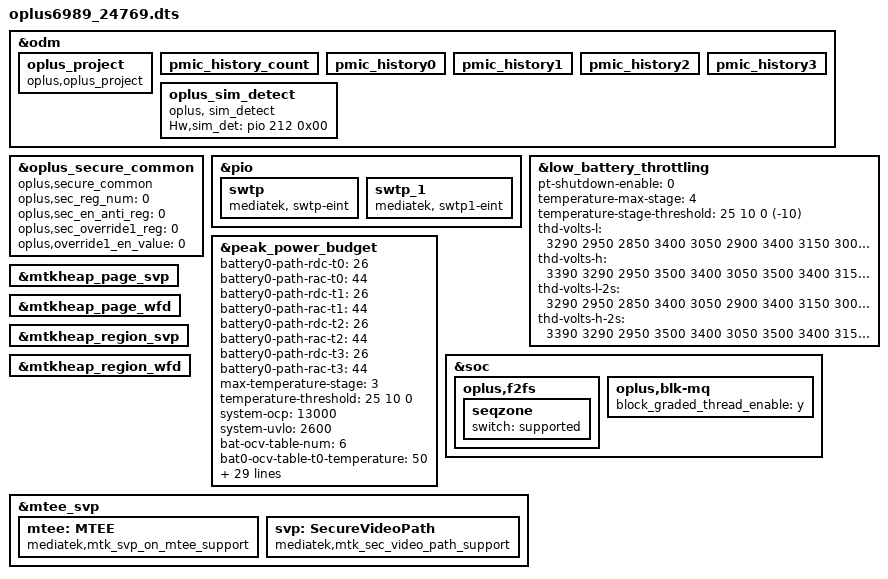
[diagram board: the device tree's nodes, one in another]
// SPDX-License-Identifier: (GPL-2.0 OR MIT)
/*
 * Copyright (C) 2022 MediaTek Inc.
 */
#include "k6989v2_64.dts"

/* Add for CaymanP(24769) fingerprint device-tree */
/* #ifdef CONFIG_UFF_FINGERPRINT */
#include "mediatek/oplus_uff_24610.dtsi"
/* #endif CONFIG_UFF_FINGERPRINT */

//#ifdef OPLUS_FEATURE_SENSOR
#include "mediatek/oplus_sensor_24622.dtsi"
//#endif
//#ifdef OPLUS_FEATURE_CHG_BASIC

//endif

&odm {
    /*OPLUS_FEATURE_OEM_OCDT oppo project start */
	oplus_project:oplus_project {
		compatible = "oplus,oplus_project";
	};

	pmic_history_count:pmic_history_count {
 	};
 	pmic_history0:pmic_history0 {
 	};
 	pmic_history1:pmic_history1 {
 	};
 	pmic_history2:pmic_history2 {
 	};
 	pmic_history3:pmic_history3 {
 	};
};

&oplus_secure_common {
    compatible = "oplus,secure_common";
    oplus,sec_reg_num = <0>;
    oplus,sec_en_anti_reg = <0>;
    oplus,sec_override1_reg = <0>;
    oplus,override1_en_value = <0>;
};
&pio {
	//#ifdef OPLUS_VENDOR_SWTP
	swtp: swtp {
		compatible = "mediatek, swtp-eint";
	};
	 swtp_1: swtp_1 {
        compatible = "mediatek, swtp1-eint";
    };
	//#endif  /*OPLUS_VENDOR_SWTP*/
};
&low_battery_throttling {
	pt-shutdown-enable = <0>;
	temperature-max-stage = <4>;
	temperature-stage-threshold = <25 10 0 (-10)>;
	thd-volts-l = <
			3290 2950 2850    //PT threshhold down
			3400 3050 2900
			3400 3150 3000
			3710 3350 3200
			3800 3560 3350>;
	thd-volts-h = <
			3390 3290 2950
			3500 3400 3050
			3500 3400 3150
			3810 3710 3350
			3900 3800 3560>;
	thd-volts-l-2s = <
			3290 2950 2850    //PT threshhold down
			3400 3050 2900
			3400 3150 3000
			3710 3350 3200
			3800 3560 3350>;
	thd-volts-h-2s = <
			3390 3290 2950
			3500 3400 3050
			3500 3400 3150
			3810 3710 3350
			3900 3800 3560>;
};
&peak_power_budget {
	battery0-path-rdc-t0 = <26>;
	battery0-path-rac-t0 = <44>;
	battery0-path-rdc-t1 = <26>;
	battery0-path-rac-t1 = <44>;
	battery0-path-rdc-t2 = <26>;
	battery0-path-rac-t2 = <44>;
	battery0-path-rdc-t3 = <26>;
	battery0-path-rac-t3 = <44>;
	max-temperature-stage = <3>;
	temperature-threshold = <25 10 0>;
	system-ocp = <13000>;
	system-uvlo = <2600>;
	bat-ocv-table-num = <6>;
	bat0-ocv-table-t0-temperature = <50>;
	bat0-ocv-table-t0-qmax = <7171>;
	bat0-ocv-table-t0-size = <100>;
	bat0-ocv-table-t0 = <
			0       44534   0
			735     44373   0
			1471    44248   0
			2206    44144   0
			2941    44044   0
			3677    43946   0
			4412    43847   0
			5147    43747   0
			5883    43642   0
			6618    43538   0
			7354    43431   0
			8089    43323   0
			8824    43209   0
			9560    43095   0
			10295   42977   0
			11030   42858   0
			11766   42737   0
			12501   42617   0
			13236   42494   0
			13972   42369   0
			14707   42246   0
			15442   42122   0
			16178   41999   0
			16913   41871   0
			17648   41751   0
			18384   41626   0
			19119   41503   0
			19855   41376   0
			20590   41221   0
			21325   40992   0
			22061   40792   0
			22796   40657   0
			23531   40533   0
			24267   40418   0
			25002   40309   0
			25737   40202   0
			26473   40102   0
			27208   39997   0
			27943   39900   0
			28679   39806   0
			29414   39711   0
			30149   39622   0
			30885   39530   0
			31620   39444   0
			32356   39359   0
			33091   39272   0
			33826   39174   0
			34562   39026   0
			35297   38872   0
			36032   38753   0
			36768   38639   0
			37503   38525   0
			38238   38416   0
			38974   38313   0
			39709   38211   0
			40444   38093   0
			41180   37962   0
			41915   37842   0
			42651   37728   0
			43386   37612   0
			44121   37507   0
			44857   37436   0
			45592   37376   0
			46327   37313   0
			47063   37240   0
			47798   37131   0
			48533   36998   0
			49269   36890   0
			50004   36773   0
			50739   36651   0
			51475   36526   0
			52210   36396   0
			52945   36257   0
			53681   36110   0
			54416   35955   0
			55152   35793   0
			55887   35630   0
			56622   35469   0
			57358   35310   0
			58093   35155   0
			58828   34998   0
			59564   34844   0
			60299   34685   0
			61034   34519   0
			61770   34336   0
			62505   34147   0
			63240   33941   0
			63976   33721   0
			64711   33488   0
			65446   33247   0
			66182   33007   0
			66917   32771   0
			67653   32531   0
			68388   32283   0
			69123   32002   0
			69859   31656   0
			70594   31184   0
			71329   30507   0
			72065   29605   0
			72800   29135   0>;
	bat0-ocv-table-t1-temperature = <25>;
	bat0-ocv-table-t1-qmax = <7208>;
	bat0-ocv-table-t1-size = <100>;
	bat0-ocv-table-t1 = <
			0       44618   0
			735     44484   0
			1471    44379   0
			2206    44288   0
			2941    44197   0
			3677    44111   0
			4412    44020   0
			5147    43924   0
			5883    43821   0
			6618    43728   0
			7354    43625   0
			8089    43514   0
			8824    43423   0
			9560    43308   0
			10295   43192   0
			11030   43081   0
			11766   42961   0
			12501   42841   0
			13236   42719   0
			13972   42583   0
			14707   42463   0
			15442   42338   0
			16178   42215   0
			16913   42083   0
			17648   41943   0
			18384   41818   0
			19119   41700   0
			19855   41575   0
			20590   41455   0
			21325   41298   0
			22061   41089   0
			22796   40867   0
			23531   40712   0
			24267   40579   0
			25002   40457   0
			25737   40347   0
			26473   40235   0
			27208   40134   0
			27943   40015   0
			28679   39931   0
			29414   39835   0
			30149   39742   0
			30885   39648   0
			31620   39556   0
			32356   39471   0
			33091   39384   0
			33826   39301   0
			34562   39218   0
			35297   39124   0
			36032   39020   0
			36768   38900   0
			37503   38786   0
			38238   38668   0
			38974   38558   0
			39709   38453   0
			40444   38349   0
			41180   38234   0
			41915   38109   0
			42651   37981   0
			43386   37861   0
			44121   37739   0
			44857   37617   0
			45592   37538   0
			46327   37469   0
			47063   37407   0
			47798   37335   0
			48533   37239   0
			49269   37082   0
			50004   36953   0
			50739   36827   0
			51475   36698   0
			52210   36568   0
			52945   36427   0
			53681   36287   0
			54416   36132   0
			55152   35973   0
			55887   35807   0
			56622   35637   0
			57358   35466   0
			58093   35303   0
			58828   35144   0
			59564   34984   0
			60299   34813   0
			61034   34645   0
			61770   34469   0
			62505   34272   0
			63240   34064   0
			63976   33837   0
			64711   33592   0
			65446   33344   0
			66182   33088   0
			66917   32836   0
			67653   32589   0
			68388   32339   0
			69123   32079   0
			69859   31752   0
			70594   31335   0
			71329   30735   0
			72065   29908   0
			72800   28918   0>;
	bat0-ocv-table-t2-temperature = <10>;
	bat0-ocv-table-t2-qmax = <7202>;
	bat0-ocv-table-t2-size = <100>;
	bat0-ocv-table-t2 = <
			0       44779   0
			735     44558   0
			1471    44421   0
			2206    44313   0
			2941    44222   0
			3677    44131   0
			4412    44039   0
			5147    43948   0
			5883    43851   0
			6618    43753   0
			7354    43654   0
			8089    43551   0
			8824    43443   0
			9560    43334   0
			10295   43226   0
			11030   43112   0
			11766   42992   0
			12501   42871   0
			13236   42745   0
			13972   42631   0
			14707   42505   0
			15442   42375   0
			16178   42250   0
			16913   42124   0
			17648   41993   0
			18384   41868   0
			19119   41743   0
			19855   41613   0
			20590   41476   0
			21325   41327   0
			22061   41152   0
			22796   40929   0
			23531   40735   0
			24267   40583   0
			25002   40454   0
			25737   40337   0
			26473   40224   0
			27208   40115   0
			27943   40012   0
			28679   39908   0
			29414   39810   0
			30149   39717   0
			30885   39622   0
			31620   39531   0
			32356   39445   0
			33091   39359   0
			33826   39270   0
			34562   39187   0
			35297   39101   0
			36032   39020   0
			36768   38929   0
			37503   38829   0
			38238   38715   0
			38974   38595   0
			39709   38483   0
			40444   38374   0
			41180   38271   0
			41915   38140   0
			42651   38008   0
			43386   37886   0
			44121   37758   0
			44857   37622   0
			45592   37532   0
			46327   37457   0
			47063   37399   0
			47798   37332   0
			48533   37255   0
			49269   37123   0
			50004   36965   0
			50739   36839   0
			51475   36715   0
			52210   36589   0
			52945   36468   0
			53681   36336   0
			54416   36194   0
			55152   36046   0
			55887   35887   0
			56622   35721   0
			57358   35550   0
			58093   35378   0
			58828   35211   0
			59564   35046   0
			60299   34880   0
			61034   34711   0
			61770   34540   0
			62505   34359   0
			63240   34165   0
			63976   33954   0
			64711   33721   0
			65446   33472   0
			66182   33224   0
			66917   32970   0
			67653   32720   0
			68388   32469   0
			69123   32213   0
			69859   31935   0
			70594   31594   0
			71329   31137   0
			72065   30927   0
			72800   30927   0>;
	bat0-ocv-table-t3-temperature = <0>;
	bat0-ocv-table-t3-qmax = <6806>;
	bat0-ocv-table-t3-size = <100>;
	bat0-ocv-table-t3 = <
			0       44506   0
			735     44350   0
			1471    44233   0
			2206    44136   0
			2941    44044   0
			3677    43951   0
			4412    43860   0
			5147    43769   0
			5883    43672   0
			6618    43574   0
			7354    43470   0
			8089    43365   0
			8824    43262   0
			9560    43148   0
			10295   43034   0
			11030   42914   0
			11766   42797   0
			12501   42676   0
			13236   42553   0
			13972   42428   0
			14707   42300   0
			15442   42171   0
			16178   42049   0
			16913   41918   0
			17648   41786   0
			18384   41651   0
			19119   41498   0
			19855   41347   0
			20590   41170   0
			21325   40974   0
			22061   40797   0
			22796   40638   0
			23531   40500   0
			24267   40373   0
			25002   40259   0
			25737   40149   0
			26473   40043   0
			27208   39935   0
			27943   39833   0
			28679   39736   0
			29414   39643   0
			30149   39546   0
			30885   39454   0
			31620   39364   0
			32356   39278   0
			33091   39192   0
			33826   39106   0
			34562   39026   0
			35297   38940   0
			36032   38853   0
			36768   38756   0
			37503   38648   0
			38238   38531   0
			38974   38418   0
			39709   38307   0
			40444   38180   0
			41180   38043   0
			41915   37917   0
			42651   37788   0
			43386   37657   0
			44121   37545   0
			44857   37458   0
			45592   37395   0
			46327   37327   0
			47063   37260   0
			47798   37146   0
			48533   36958   0
			49269   36804   0
			50004   36674   0
			50739   36554   0
			51475   36431   0
			52210   36297   0
			52945   36164   0
			53681   36025   0
			54416   35865   0
			55152   35710   0
			55887   35531   0
			56622   35349   0
			57358   35165   0
			58093   34989   0
			58828   34820   0
			59564   34626   0
			60299   34455   0
			61034   34256   0
			61770   34048   0
			62505   33849   0
			63240   33617   0
			63976   33367   0
			64711   33136   0
			65446   32886   0
			66182   32620   0
			66917   32371   0
			67653   32142   0
			68388   32142   0
			69123   32142   0
			69859   32142   0
			70594   32142   0
			71329   32142   0
			72065   32142   0
			72800   32142   0>;
	bat-ocv-table-t4-temperature = <(-10)>;
	bat-ocv-table-t4-qmax = <6359>;
	bat-ocv-table-t4-size = <100>;
	bat-ocv-table-t4 = <
			0       44692   0
			735     44484   0
			1471    44348   0
			2206    44232   0
			2941    44131   0
			3677    44031   0
			4412    43934   0
			5147    43843   0
			5883    43739   0
			6618    43641   0
			7354    43535   0
			8089    43433   0
			8824    43324   0
			9560    43216   0
			10295   43104   0
			11030   42988   0
			11766   42871   0
			12501   42748   0
			13236   42627   0
			13972   42502   0
			14707   42377   0
			15442   42247   0
			16178   42117   0
			16913   41986   0
			17648   41848   0
			18384   41706   0
			19119   41558   0
			19855   41407   0
			20590   41238   0
			21325   41069   0
			22061   40903   0
			22796   40743   0
			23531   40594   0
			24267   40455   0
			25002   40330   0
			25737   40207   0
			26473   40098   0
			27208   39985   0
			27943   39876   0
			28679   39773   0
			29414   39677   0
			30149   39583   0
			30885   39485   0
			31620   39400   0
			32356   39309   0
			33091   39224   0
			33826   39137   0
			34562   39051   0
			35297   38969   0
			36032   38884   0
			36768   38793   0
			37503   38707   0
			38238   38611   0
			38974   38517   0
			39709   38413   0
			40444   38299   0
			41180   38185   0
			41915   38061   0
			42651   37931   0
			43386   37806   0
			44121   37674   0
			44857   37540   0
			45592   37438   0
			46327   37365   0
			47063   37300   0
			47798   37227   0
			48533   37152   0
			49269   37001   0
			50004   36761   0
			50739   36582   0
			51475   36421   0
			52210   36276   0
			52945   36133   0
			53681   35980   0
			54416   35815   0
			55152   35633   0
			55887   35447   0
			56622   35244   0
			57358   35036   0
			58093   34822   0
			58828   34594   0
			59564   34366   0
			60299   34142   0
			61034   33910   0
			61770   33673   0
			62505   33439   0
			63240   33221   0
			63976   33221   0
			64711   33221   0
			65446   33221   0
			66182   33221   0
			66917   33221   0
			67653   33221   0
			68388   33221   0
			69123   33221   0
			69859   33221   0
			70594   33221   0
			71329   33221   0
			72065   33221   0
			72800   33221   0>;
	bat-ocv-table-t5-temperature = <(-20)>;
	bat-ocv-table-t5-qmax = <5815>;
	bat-ocv-table-t5-size = <100>;
	bat-ocv-table-t5 = <
			0       44785   0
			735     44427   0
			1471    44211   0
			2206    44035   0
			2941    43872   0
			3677    43724   0
			4412    43583   0
			5147    43446   0
			5883    43310   0
			6618    43177   0
			7354    43045   0
			8089    42920   0
			8824    42789   0
			9560    42664   0
			10295   42534   0
			11030   42403   0
			11766   42278   0
			12501   42148   0
			13236   42034   0
			13972   41908   0
			14707   41772   0
			15442   41640   0
			16178   41503   0
			16913   41365   0
			17648   41229   0
			18384   41087   0
			19119   40946   0
			19855   40802   0
			20590   40657   0
			21325   40515   0
			22061   40373   0
			22796   40237   0
			23531   40105   0
			24267   39983   0
			25002   39868   0
			25737   39749   0
			26473   39642   0
			27208   39540   0
			27943   39441   0
			28679   39344   0
			29414   39254   0
			30149   39162   0
			30885   39071   0
			31620   38992   0
			32356   38902   0
			33091   38824   0
			33826   38741   0
			34562   38667   0
			35297   38582   0
			36032   38498   0
			36768   38423   0
			37503   38337   0
			38238   38257   0
			38974   38171   0
			39709   38086   0
			40444   37990   0
			41180   37892   0
			41915   37794   0
			42651   37691   0
			43386   37582   0
			44121   37481   0
			44857   37387   0
			45592   37317   0
			46327   37246   0
			47063   37189   0
			47798   37125   0
			48533   37029   0
			49269   36866   0
			50004   36656   0
			50739   36453   0
			51475   36278   0
			52210   36113   0
			52945   35954   0
			53681   35784   0
			54416   35599   0
			55152   35406   0
			55887   35193   0
			56622   34966   0
			57358   34721   0
			58093   34567   0
			58828   34567   0
			59564   34567   0
			60299   34567   0
			61034   34567   0
			61770   34567   0
			62505   34567   0
			63240   34567   0
			63976   34567   0
			64711   34567   0
			65446   34567   0
			66182   34567   0
			66917   34567   0
			67653   34567   0
			68388   34567   0
			69123   34567   0
			69859   34567   0
			70594   34567   0
			71329   34567   0
			72065   34567   0
			72800   34567   0>;
};

&soc {
	oplus,f2fs {
		seqzone {
			switch = "supported";
		};
	};

	//Kernel.Storage, 2024/10/9, add for blk-mq.c block_graded_thread_enable
	oplus,blk-mq {
		block_graded_thread_enable = "y";
	};
};
/*#ifdef OPLUS_FEATURE_SECURITY_COMMON*/

&mtkheap_page_svp {
    status = "ok";
};
&mtkheap_page_wfd {
    status = "ok";
};
&mtkheap_region_svp {
    status = "ok";
};
&mtkheap_region_wfd {
    status = "ok";
};
&mtee_svp {
	mtee: MTEE {
		compatible = "mediatek,mtk_svp_on_mtee_support";
	};
	svp: SecureVideoPath {
		compatible = "mediatek,mtk_sec_video_path_support";
	};
};
/*#endif OPLUS_FEATURE_SECURITY_COMMON*/

&odm {
/* Add for sim detect */
    oplus_sim_detect {
        compatible = "oplus, sim_detect";
        Hw,sim_det = <&pio 212 0x00>;
    };
};

#include <oplus6989_24769/cust.dtsi>
#include "mediatek/nfc/mt6989_24769_thn31f.dtsi"
#include "mediatek/cust_mt6989_caymanp_24769_camera_v4l2.dtsi"
#include "mediatek/cust_mt6989_24749_audio.dtsi"
#include "mediatek/oplus_misc_24749.dtsi"
#include "mediatek/oplus_tp_24622.dtsi"
#include "mediatek/oplus_charge_24769.dtsi"
#include "oplus_connectivity_24749.dtsi"
#include "mediatek/display/oplus6989_24769_display.dtsi"
/*End of this file, DO NOT ADD ANYTHING HERE*/
